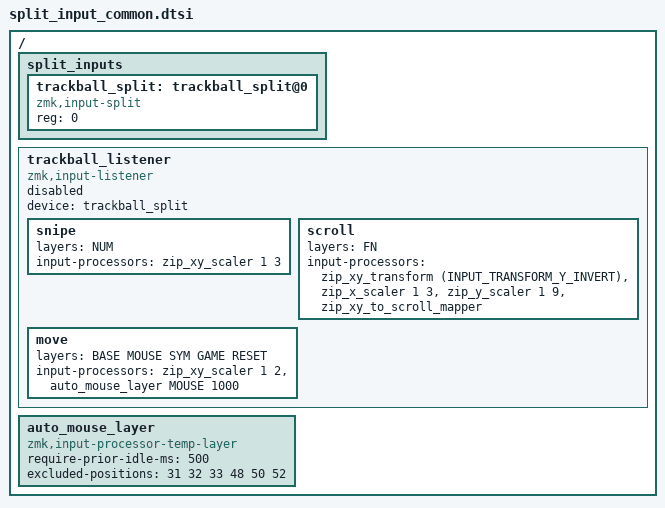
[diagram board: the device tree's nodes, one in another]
#include <dt-bindings/zmk/input_transform.h>
#include <input/processors.dtsi>

/* Same layer indexes as config/charybdis.keymap. */
#define BASE 0
#define MOUSE 1
#define NUM 2
#define SYM 3
#define FN 4
#define GAME 5
#define RESET 6

/ {
  split_inputs {
    #address-cells = <1>;
    #size-cells = <0>;

    trackball_split: trackball_split@0 {
      compatible = "zmk,input-split";
      reg = <0>;
    };
  };

  /*
   * charybdis_zmk trackball modes, expressed with ZMK main processors.
   * Cursor: 1/2 speed, auto-mouse layer for 1000 ms.
   * Precision on Number: 1/3. Scroll on Function: Y inverted,
   * horizontal 1/3, vertical 1/9 (listener divisor 3, then wheel scaler 3).
   */
  trackball_listener: trackball_listener {
    compatible = "zmk,input-listener";
    status = "disabled";
    device = <&trackball_split>;

    snipe {
      layers = <NUM>;
      input-processors = <&zip_xy_scaler 1 3>;
    };

    scroll {
      layers = <FN>;
      input-processors = <&zip_xy_transform (INPUT_TRANSFORM_Y_INVERT)>, <&zip_x_scaler 1 3>, <&zip_y_scaler 1 9>, <&zip_xy_to_scroll_mapper>;
    };

    move {
      layers = <BASE MOUSE SYM GAME RESET>;
      input-processors = <&zip_xy_scaler 1 2>, <&auto_mouse_layer MOUSE 1000>;
    };
  };

  auto_mouse_layer: auto_mouse_layer {
    compatible = "zmk,input-processor-temp-layer";
    #input-processor-cells = <2>;
    require-prior-idle-ms = <500>;
    excluded-positions = <31 32 33 48 50 52>;
  };
};
